VERSION ""

NS_ :

BS_:

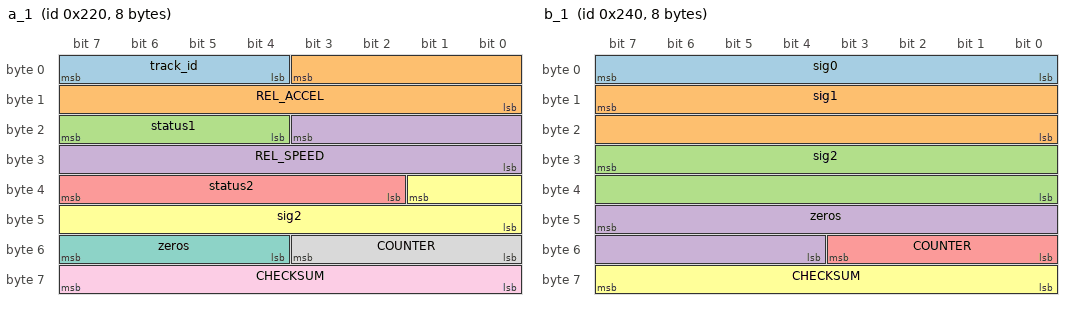
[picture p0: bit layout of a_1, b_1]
BO_ 544 a_1: 8 XXX
 SG_ track_id : 7|4@0+ (1,0) [0|15] "" XXX
 SG_ REL_ACCEL : 3|12@0+ (1,0) [0|31] "" XXX
 SG_ status1 : 23|4@0+ (1,0) [0|15] "" XXX
 SG_ REL_SPEED : 19|12@0+ (1,0) [0|65535] "" XXX
 SG_ status2 : 39|6@0+ (1,0) [0|15] "" XXX
 SG_ sig2 : 33|10@0+ (1,0) [0|255] "" XXX
 SG_ zeros : 55|4@0+ (1,0) [0|15] "" XXX
 SG_ COUNTER : 51|4@0+ (1,0) [0|15] "" XXX
 SG_ CHECKSUM : 63|8@0+ (1,0) [0|255] "" XXX

BO_ 576 b_1: 8 XXX
 SG_ sig0 : 7|8@0+ (1,0) [0|255] "" XXX
 SG_ sig1 : 15|16@0+ (1,0) [0|65535] "" XXX
 SG_ sig2 : 31|16@0+ (1,0) [0|255] "" XXX
 SG_ zeros : 47|12@0+ (1,0) [0|255] "" XXX
 SG_ COUNTER : 51|4@0+ (1,0) [0|15] "" XXX
 SG_ CHECKSUM : 63|8@0+ (1,0) [0|255] "" XXX

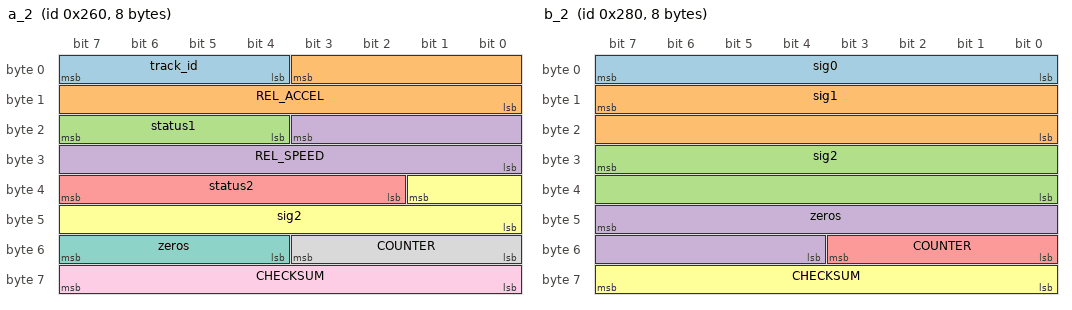
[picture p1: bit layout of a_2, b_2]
BO_ 608 a_2: 8 XXX
 SG_ track_id : 7|4@0+ (1,0) [0|15] "" XXX
 SG_ REL_ACCEL : 3|12@0+ (1,0) [0|31] "" XXX
 SG_ status1 : 23|4@0+ (1,0) [0|15] "" XXX
 SG_ REL_SPEED : 19|12@0+ (1,0) [0|65535] "" XXX
 SG_ status2 : 39|6@0+ (1,0) [0|15] "" XXX
 SG_ sig2 : 33|10@0+ (1,0) [0|255] "" XXX
 SG_ zeros : 55|4@0+ (1,0) [0|15] "" XXX
 SG_ COUNTER : 51|4@0+ (1,0) [0|15] "" XXX
 SG_ CHECKSUM : 63|8@0+ (1,0) [0|255] "" XXX

BO_ 640 b_2: 8 XXX
 SG_ sig0 : 7|8@0+ (1,0) [0|255] "" XXX
 SG_ sig1 : 15|16@0+ (1,0) [0|65535] "" XXX
 SG_ sig2 : 31|16@0+ (1,0) [0|255] "" XXX
 SG_ zeros : 47|12@0+ (1,0) [0|255] "" XXX
 SG_ COUNTER : 51|4@0+ (1,0) [0|15] "" XXX
 SG_ CHECKSUM : 63|8@0+ (1,0) [0|255] "" XXX

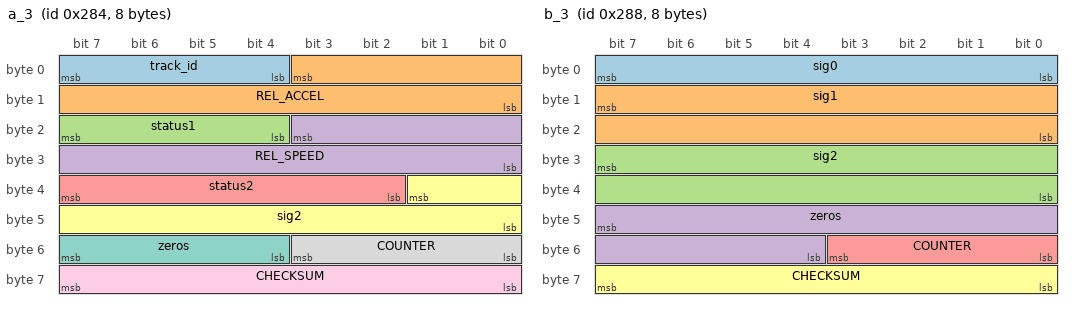
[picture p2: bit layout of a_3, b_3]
BO_ 644 a_3: 8 XXX
 SG_ track_id : 7|4@0+ (1,0) [0|15] "" XXX
 SG_ REL_ACCEL : 3|12@0+ (1,0) [0|31] "" XXX
 SG_ status1 : 23|4@0+ (1,0) [0|15] "" XXX
 SG_ REL_SPEED : 19|12@0+ (1,0) [0|65535] "" XXX
 SG_ status2 : 39|6@0+ (1,0) [0|15] "" XXX
 SG_ sig2 : 33|10@0+ (1,0) [0|255] "" XXX
 SG_ zeros : 55|4@0+ (1,0) [0|15] "" XXX
 SG_ COUNTER : 51|4@0+ (1,0) [0|15] "" XXX
 SG_ CHECKSUM : 63|8@0+ (1,0) [0|255] "" XXX

BO_ 648 b_3: 8 XXX
 SG_ sig0 : 7|8@0+ (1,0) [0|255] "" XXX
 SG_ sig1 : 15|16@0+ (1,0) [0|65535] "" XXX
 SG_ sig2 : 31|16@0+ (1,0) [0|255] "" XXX
 SG_ zeros : 47|12@0+ (1,0) [0|255] "" XXX
 SG_ COUNTER : 51|4@0+ (1,0) [0|15] "" XXX
 SG_ CHECKSUM : 63|8@0+ (1,0) [0|255] "" XXX

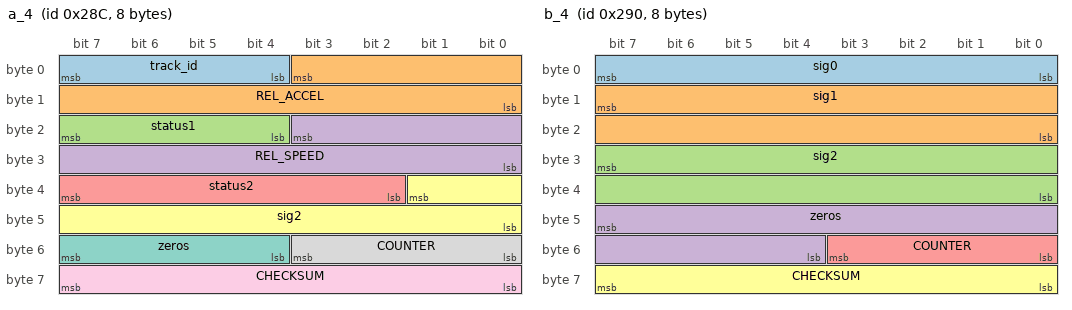
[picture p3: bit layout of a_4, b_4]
BO_ 652 a_4: 8 XXX
 SG_ track_id : 7|4@0+ (1,0) [0|15] "" XXX
 SG_ REL_ACCEL : 3|12@0+ (1,0) [0|31] "" XXX
 SG_ status1 : 23|4@0+ (1,0) [0|15] "" XXX
 SG_ REL_SPEED : 19|12@0+ (1,0) [0|65535] "" XXX
 SG_ status2 : 39|6@0+ (1,0) [0|15] "" XXX
 SG_ sig2 : 33|10@0+ (1,0) [0|255] "" XXX
 SG_ zeros : 55|4@0+ (1,0) [0|15] "" XXX
 SG_ COUNTER : 51|4@0+ (1,0) [0|15] "" XXX
 SG_ CHECKSUM : 63|8@0+ (1,0) [0|255] "" XXX

BO_ 656 b_4: 8 XXX
 SG_ sig0 : 7|8@0+ (1,0) [0|255] "" XXX
 SG_ sig1 : 15|16@0+ (1,0) [0|65535] "" XXX
 SG_ sig2 : 31|16@0+ (1,0) [0|255] "" XXX
 SG_ zeros : 47|12@0+ (1,0) [0|255] "" XXX
 SG_ COUNTER : 51|4@0+ (1,0) [0|15] "" XXX
 SG_ CHECKSUM : 63|8@0+ (1,0) [0|255] "" XXX

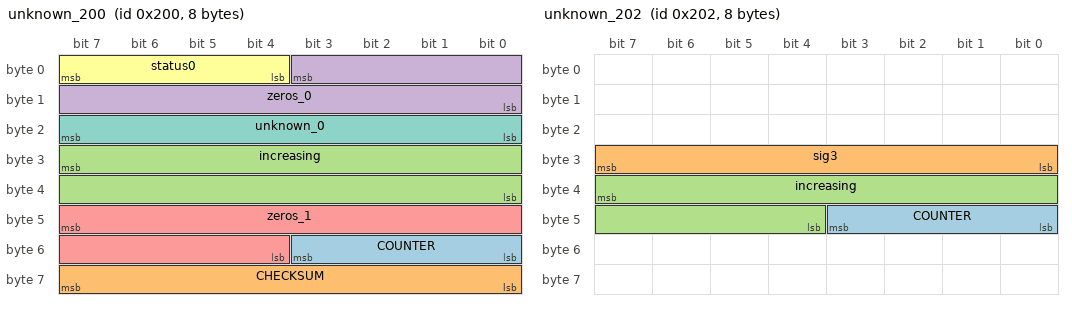
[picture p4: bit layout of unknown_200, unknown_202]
BO_ 512 unknown_200: 8 XXX
 SG_ COUNTER : 51|4@0+ (1,0) [0|15] "" XXX
 SG_ CHECKSUM : 63|8@0+ (1,0) [0|255] "" XXX
 SG_ increasing : 31|16@0+ (1,0) [0|255] "" XXX
 SG_ zeros_0 : 3|12@0+ (1,0) [0|63] "" XXX
 SG_ zeros_1 : 47|12@0+ (1,0) [0|63] "" XXX
 SG_ status0 : 7|4@0+ (1,0) [0|15] "" XXX
 SG_ unknown_0 : 23|8@0+ (1,0) [0|255] "" XXX

BO_ 514 unknown_202: 8 XXX
 SG_ COUNTER : 43|4@0+ (1,0) [0|15] "" XXX
 SG_ sig3 : 31|8@0+ (1,0) [0|65535] "" XXX
 SG_ increasing : 39|12@0+ (1,0) [0|15] "" XXX

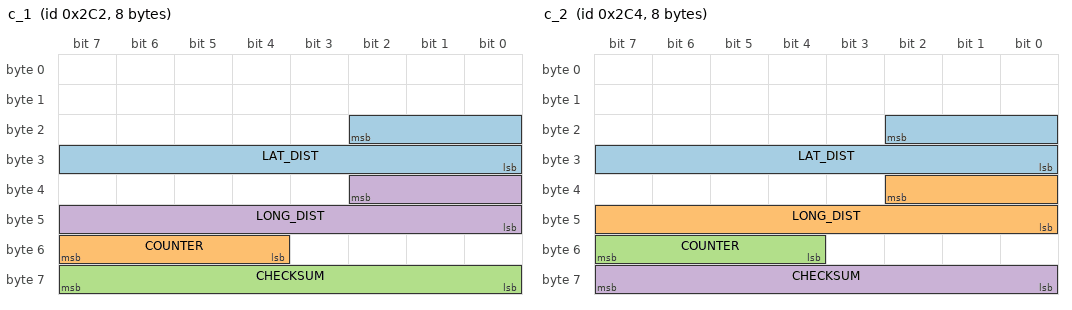
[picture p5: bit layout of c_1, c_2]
BO_ 706 c_1: 8 XXX
 SG_ LAT_DIST : 18|11@0+ (0.005,-1000) [0|2047] "m" XXX
 SG_ COUNTER : 55|4@0+ (1,0) [0|15] "" XXX
 SG_ CHECKSUM : 63|8@0+ (1,0) [0|255] "" XXX
 SG_ LONG_DIST : 34|11@0+ (0.073,0) [0|255] "m" XXX

BO_ 708 c_2: 8 XXX
 SG_ LAT_DIST : 18|11@0+ (0.005,-1000) [0|2047] "m" XXX
 SG_ LONG_DIST : 34|11@0+ (0.073,0) [0|255] "m" XXX
 SG_ COUNTER : 55|4@0+ (1,0) [0|15] "" XXX
 SG_ CHECKSUM : 63|8@0+ (1,0) [0|255] "" XXX

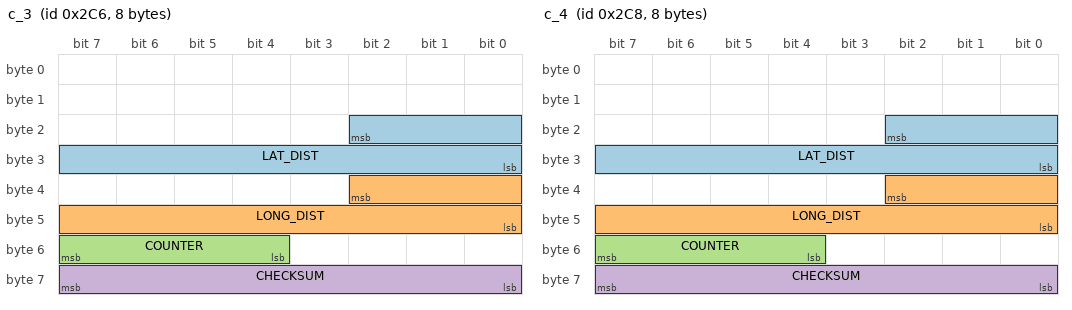
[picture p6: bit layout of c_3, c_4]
BO_ 710 c_3: 8 XXX
 SG_ LAT_DIST : 18|11@0+ (0.005,-1000) [0|2047] "m" XXX
 SG_ LONG_DIST : 34|11@0+ (0.073,0) [0|255] "m" XXX
 SG_ COUNTER : 55|4@0+ (1,0) [0|15] "" XXX
 SG_ CHECKSUM : 63|8@0+ (1,0) [0|255] "" XXX

BO_ 712 c_4: 8 XXX
 SG_ LAT_DIST : 18|11@0+ (0.005,-1000) [0|2047] "m" XXX
 SG_ LONG_DIST : 34|11@0+ (0.073,0) [0|255] "m" XXX
 SG_ COUNTER : 55|4@0+ (1,0) [0|15] "" XXX
 SG_ CHECKSUM : 63|8@0+ (1,0) [0|255] "" XXX

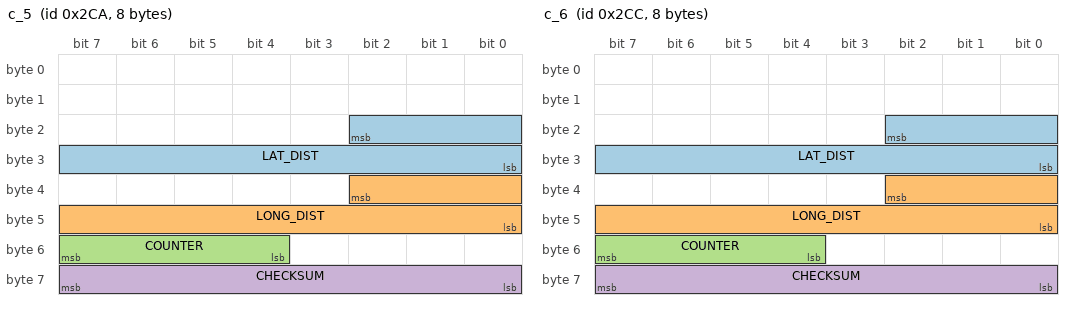
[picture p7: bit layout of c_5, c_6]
BO_ 714 c_5: 8 XXX
 SG_ LAT_DIST : 18|11@0+ (0.005,-1000) [0|2047] "m" XXX
 SG_ LONG_DIST : 34|11@0+ (0.073,0) [0|255] "m" XXX
 SG_ COUNTER : 55|4@0+ (1,0) [0|15] "" XXX
 SG_ CHECKSUM : 63|8@0+ (1,0) [0|255] "" XXX

BO_ 716 c_6: 8 XXX
 SG_ LAT_DIST : 18|11@0+ (0.005,-1000) [0|2047] "m" XXX
 SG_ LONG_DIST : 34|11@0+ (0.073,0) [0|255] "m" XXX
 SG_ COUNTER : 55|4@0+ (1,0) [0|15] "" XXX
 SG_ CHECKSUM : 63|8@0+ (1,0) [0|255] "" XXX

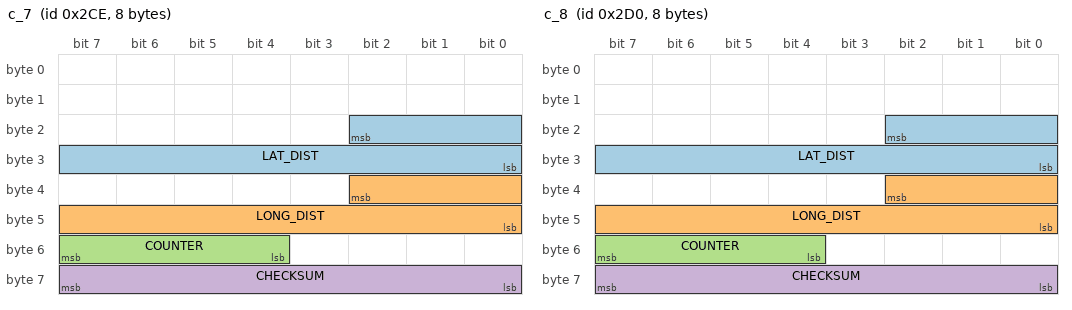
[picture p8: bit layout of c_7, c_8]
BO_ 718 c_7: 8 XXX
 SG_ LAT_DIST : 18|11@0+ (0.005,-1000) [0|2047] "m" XXX
 SG_ LONG_DIST : 34|11@0+ (0.073,0) [0|255] "m" XXX
 SG_ COUNTER : 55|4@0+ (1,0) [0|15] "" XXX
 SG_ CHECKSUM : 63|8@0+ (1,0) [0|255] "" XXX

BO_ 720 c_8: 8 XXX
 SG_ LAT_DIST : 18|11@0+ (0.005,-1000) [0|2047] "m" XXX
 SG_ LONG_DIST : 34|11@0+ (0.073,0) [0|255] "m" XXX
 SG_ COUNTER : 55|4@0+ (1,0) [0|15] "" XXX
 SG_ CHECKSUM : 63|8@0+ (1,0) [0|255] "" XXX

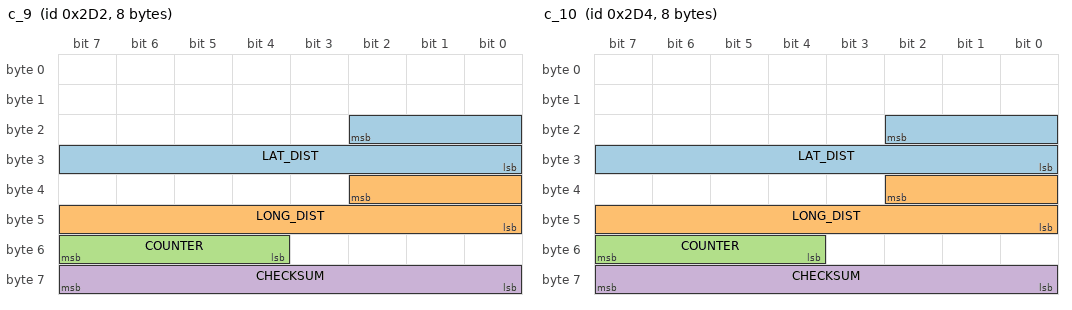
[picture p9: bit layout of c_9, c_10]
BO_ 722 c_9: 8 XXX
 SG_ LAT_DIST : 18|11@0+ (0.005,-1000) [0|2047] "m" XXX
 SG_ LONG_DIST : 34|11@0+ (0.073,0) [0|255] "m" XXX
 SG_ COUNTER : 55|4@0+ (1,0) [0|15] "" XXX
 SG_ CHECKSUM : 63|8@0+ (1,0) [0|255] "" XXX

BO_ 724 c_10: 8 XXX
 SG_ LAT_DIST : 18|11@0+ (0.005,-1000) [0|2047] "m" XXX
 SG_ LONG_DIST : 34|11@0+ (0.073,0) [0|255] "m" XXX
 SG_ COUNTER : 55|4@0+ (1,0) [0|15] "" XXX
 SG_ CHECKSUM : 63|8@0+ (1,0) [0|255] "" XXX

BO_ 674 d_1: 8 XXX
 SG_ REL_SPEED : 17|10@0+ (0.2857,-146.278) [0|1023] "m/s" XXX

BO_ 676 d_2: 8 XXX
 SG_ REL_SPEED : 17|10@0+ (0.2857,-146.278) [0|1023] "m/s" XXX

BO_ 678 d_3: 8 XXX
 SG_ REL_SPEED : 17|10@0+ (0.2857,-146.278) [0|1023] "m/s" XXX

BO_ 680 d_4: 8 XXX
 SG_ REL_SPEED : 17|10@0+ (0.2857,-146.278) [0|1023] "m/s" XXX

BO_ 682 d_5: 8 XXX
 SG_ REL_SPEED : 17|10@0+ (0.2857,-146.278) [0|1023] "m/s" XXX

BO_ 684 d_6: 8 XXX
 SG_ REL_SPEED : 17|10@0+ (0.2857,-146.278) [0|1023] "m/s" XXX

BO_ 686 d_7: 8 XXX
 SG_ REL_SPEED : 17|10@0+ (0.2857,-146.278) [0|1023] "m/s" XXX

BO_ 688 d_8: 8 XXX
 SG_ REL_SPEED : 17|10@0+ (0.2857,-146.278) [0|1023] "m/s" XXX

BO_ 690 d_9: 8 XXX
 SG_ REL_SPEED : 17|10@0+ (0.2857,-146.278) [0|1023] "m/s" XXX

BO_ 692 d_10: 8 XXX
 SG_ REL_SPEED : 17|10@0+ (0.2857,-146.278) [0|1023] "m/s" XXX

BO_ 672 NEW_MSG_5: 8 XXX
 SG_ NEW_SIGNAL_1 : 9|10@0+ (1,0) [0|1023] "" XXX
 SG_ NEW_SIGNAL_2 : 45|10@0+ (1,0) [0|1023] "" XXX

CM_ SG_ 80 Checksumme_Airbag_1 "Checksum Airbag_1";
CM_ SG_ 80 Zaehler_Airbag_1 "Counter Airbag_1";

CM_ SG_ 210 LM_Offset "centiNewton-meters for ease of calculation without FP math in Panda";
CM_ SG_ 210 Vib_Amp "Steering wheel haptic, amplitude";
CM_ SG_ 210 Vib_Freq "Steering wheel haptic, frequency";

CM_ SG_ 416 Zaehler_Bremse_1 "Counter Bremse_1";

CM_ SG_ 640 inneres_Motor_Moment "Engine Indicated Torque";
CM_ SG_ 640 Fahrerwunschmoment "Driver Requested Torque";
CM_ SG_ 640 mechanisches_Motor_Verlustmomen "Mechanical Torque Loss";
CM_ SG_ 640 Fahrpedalwert_oder_Drosselklapp "Accelerator Pedal or Throttle Position";
CM_ SG_ 640 Motordrehzahl "Engine Speed";
CM_ SG_ 640 Momentenangaben_ungenau "Approximate Torque Values";
CM_ SG_ 640 inneres_Motor_Moment_ohne_exter "Inner torque without external";

CM_ SG_ 644 MOB_CHECKSUM "Checksum MOB";
CM_ SG_ 644 MOB_COUNTER "Counter MOB";

CM_ SG_ 648 Minimales_Motormoment_bei_Zuend "Minimum Torque Adjustment";
CM_ SG_ 648 Begrenzungsmoment "Maximum Inner Torque";
CM_ SG_ 648 Bremstestschalter "Brake Test Switch";
CM_ SG_ 648 Soll_Geschwindigkeit_bei_GRA_Be "Desired Vehicle Speed";
CM_ SG_ 648 Bremslichtschalter "Brake Light Switch";
CM_ SG_ 648 Leerlaufsolldrehzahl__Motor_2_ "Target Idle Speed";
CM_ SG_ 648 Fahrzeuggeschwindigkeit "Vehicle Speed";
CM_ SG_ 648 Kuehlmitteltemperatur__Motor_2_ "Coolant Temperature";

CM_ SG_ 896 Drosselklappenpoti "Throttle Position";
CM_ SG_ 896 Motor_Wunschdrehzahl "Desired engine speed";
CM_ SG_ 896 Motordrehzahlbeeinflussung "Shift Target Influence";
CM_ SG_ 896 Fahrpedal_Rohsignal "Accelerator Pedal Position";
CM_ SG_ 896 Ansauglufttemperatur "Intake Air Temperature";
CM_ SG_ 896 Kein_E_Gas "ETB flag";
CM_ SG_ 896 Kein_Start_Stop "Start/stop flag";
CM_ SG_ 896 Rad_Wunschmoment "Desired wheel torque";

CM_ SG_ 912 GK1_Fa_Tuerkont "Status of the driver's door rotary latch";
CM_ SG_ 912 BSK_HL_geoeffnet "Status of the rear left door rotary latch";
CM_ SG_ 912 BSK_HR_geoeffnet "Status of the rear right door rotary latch";
CM_ SG_ 912 BSK_BT_geoeffnet "Status of the passenger door rotary latch";
CM_ SG_ 912 BSK_HD_Hauptraste "Status of trunk lid main detent";

CM_ SG_ 1088 Zaehler_Getriebe_1 "Counter Getriebe_1";
CM_ SG_ 1088 Waehlhebelposition__Getriebe_1_ "Gear Selector Position";
CM_ SG_ 1088 inneres_Soll_Motormoment "Desired Inner Torque";
CM_ SG_ 1088 Schaltabsicht "Shift Intent";
CM_ SG_ 1088 Wandlerverlustmoment "Converter Torque Loss";

CM_ SG_ 1056 Fehlerstatus_Aussentemp__4_1 "ambient temp error";
CM_ SG_ 1056 Fehlerstatus_Oeltemperatur_4_1 "oil temp error";
CM_ SG_ 1056 Fehlerst__Kuehlmitteltemp__4_1 "water temp error";
CM_ SG_ 1056 Aussentemperatur_gefiltert "outside temp, filtered";
CM_ SG_ 1056 Oeltemperatur_4_1 "kombi oil temperature";
CM_ SG_ 1056 Kuehlmitteltemp__4_1__Kombi_2_ "kombi coolant temperature";

CM_ SG_ 1096 Zaehler_Waehlhebel_1 "Counter Waehlhebel_1";

CM_ SG_ 1152 CHECKSUM "Checksum Motor_5";
CM_ SG_ 1152 Anlasser_Ausspuren "Starter Disable";
CM_ SG_ 1152 Anlasser_Freigabe "Starter Release";
CM_ SG_ 1152 Klimadrucksignal__Motor_5_ "Air conditioning pressure signal";
CM_ SG_ 1152 Kraftstoffverbrauchssignal "Fuel consumption signal";
CM_ SG_ 1152 K_hlerluefteransteuerung "Cooling fan control signal";
CM_ SG_ 1152 Klimakompressor_Leistungsreduzi "Air conditioning compressor power reduction flag";
CM_ SG_ 1152 Klimakompressor_aus__Motor_5_ "Air conditioning compressor";
CM_ SG_ 1152 Anlasser_Freigabe "Starter release";
CM_ SG_ 1152 OBD_2_Lampe "OBD light";
CM_ SG_ 1152 E_Gas_Lampe "ETB light";
CM_ SG_ 1152 Ladekontroll_Lampe "Charge light";
CM_ SG_ 1152 Vorgluehlampe__Motor_5_ "Glow light";

CM_ SG_ 1160 Zaehler_Motor_6 "Counter Motor_6";
CM_ SG_ 1160 Hoeheninfo__Motor_6_ "Altitude Correction";
CM_ SG_ 1160 Istmoment_f_r_Getriebe "Actual torque for gear";
CM_ SG_ 1160 Sollmoment_f_r_Getriebe "Target torque for gearbox";
CM_ SG_ 1160 Checksumme_Motor_6 "Checksum Motor_6";
CM_ SG_ 1160 GRA_Sollbeschleunigung "GRA target acceleration";
CM_ SG_ 1160 Ruckmeldung_Momenten "Feedback torque-integral gear intervention";

CM_ SG_ 1344 Zahler_Getriebe_2 "Counter Getriebe_2";
CM_ SG_ 1344 Hochschaltlampe "Upshift Flag";

CM_ SG_ 1386 ACA_V_Wunsch "255=unset";

CM_ SG_ 1408 Zaehler_Motor_Flexia "Counter Motor_Flexia";
CM_ SG_ 1408 Verbrennungsart "Type of combustion";
CM_ SG_ 1408 Max_Drehmoment "Maximum torque";
CM_ SG_ 1408 Drehzahl_MaxNorm "RPM of maximum torque";
CM_ SG_ 1408 Hubraum "Displacement";
CM_ SG_ 1408 Anzahl_Zylinder "Number of cylinders";
CM_ SG_ 1408 Anzahl_Ventile "Number of valves";
CM_ SG_ 1408 Ansaugsystem "Induction System";
CM_ SG_ 1408 Motorleistung "Maximum engine power";

CM_ SG_ 1416 Ladedruck "Boost Pressure";
CM_ SG_ 1416 Motordrehzahlgradient "Engine speed gradient";
CM_ SG_ 1416 Hoeheninfo__Motor_7_ "Altitude correction factor";
CM_ SG_ 1416 Oltemperatur "Oil temperature";

CM_ SG_ 1470 LDW_Direction "0=right,1=left";
CM_ SG_ 1470 XX_DLCORTLC1 "Might be DLC or TLC";
CM_ SG_ 1470 XX_DLCORTLC2 "Might be DLC or TLC, might have wrong size";

CM_ SG_ 1550 MFA_v_Signal_02 "0=km/h, 1=mph";

VAL_ 870 AWV_Text 0 "kein_Text" 1 "FrontAssist_aus" 2 "FrontAssist_startet" 3 "FrontAssist_Warnung" 4 "FrontAssist_Sens_reinig" 5 "FrontAssist_Failure" 6 "FrontAssist_Demo" 7 "Vorhalt" 8 "Bremsung_wird_gerade_durchgefuehrt" 9 "Sensor_not_verfuegbar" 10 "Sensor_reinigen" 11 "Service_notwendig_Failure" 12 "Funktion_vom_Fahrer_deactivated" 13 "Funktion_vom_Fahrer_activated" 14 "FrontAssist_zur_Zeit_not_verfuegbar__rev_Failure";
VAL_ 870 AWV_1_Freigabe 0 "nicht_freigegeben" 1 "freigegeben";
VAL_ 870 AWV_1_Prefill 0 "keine_Prefill_Anf" 1 "Prefill_Anf";
VAL_ 870 AWV_1_Parameter 0 "Defaultparametersatz" 1 "Par_leicht_erh_Empf" 2 "Par_erh_Empf" 3 "Par_hoechster_Empf";
VAL_ 870 AWV_only 0 "ACC_und_AWV_verbaut" 1 "AWV_ohne_ACC_verbaut";
VAL_ 870 AWV_CityANB_Auspraegung 0 "autom_Bremsung_im_ges_vBereich" 1 "autom_Bremsung_im_def_vBereich";
VAL_ 870 AWV_Halten 0 "keine_Anforderung" 1 "Anforderung_das_Fzg_im_Stillstand_zu_halten";
VAL_ 870 ANB_Teilbremsung_Freigabe 0 "Teilbremsung_nicht_freigegeben" 1 "Teilbremsung_freigegeben";
VAL_ 870 AWV_2_Status 0 "Lampe_aus" 1 "Lampe_ein";
VAL_ 870 AWV_2_Fehler 0 "Lampe_aus" 1 "Lampe_ein";
VAL_ 870 AWV_2_SU_Warnzeit 0 "frueh" 1 "normal" 2 "spaet" 3 "adaptiv";
VAL_ 870 AWV_2_SU_Bremsruck 0 "Bremsruck_deaktiviert" 1 "Bremsruck_aktiviert";
VAL_ 870 AWV_2_SU_Gong 0 "Gong_deaktiviert" 1 "Gong_aktiviert";
VAL_ 870 AWV_2_SU_Lampe 0 "Lampe_deaktiviert" 1 "Lampe_aktiviert";
VAL_ 870 AWV_2_Umfeldwarn 0 "keine_Warnung" 1 "Warnung";
VAL_ 870 AWV_2_Freigabe 0 "keine_Ruckfreigabe" 1 "Ruckfreigabe";
VAL_ 870 AWV_2_Ruckprofil 0 "kein_Ruck" 1 "Ruckprofil_1" 2 "Ruckprofil_2" 3 "Ruckprofil_3" 4 "Ruckprofil_4" 5 "Ruckprofil_5" 6 "not_erlaubt" 7 "not_erlaubt";
VAL_ 870 AWV_2_Warnton 0 "Aus" 1 "Ein";
VAL_ 870 AWV_2_Warnsymbol 0 "Aus" 1 "Ein";
VAL_ 870 AWV_Infoton 0 "Aus" 1 "Ein";
VAL_ 870 AWV_2_Gurtstraffer 0 "Gurt_not_straffen" 1 "Gurt_straffen";
VAL_ 870 AWV_Konfiguration_Menueanf 0 "Menue_deaktivieren" 1 "Menue_aktivieren";
VAL_ 870 AWV_Konfiguration_Vorw_Menueanf 0 "Menue_deaktivieren" 1 "Menue_aktivieren";
VAL_ 870 AWV_Konfiguration_Status 0 "AWV_inaktiv" 1 "AWV_aktiv";
VAL_ 870 AWV_Konfiguration_Vorw_Status 0 "AWV_Vorwarnung_inaktiv" 1 "AWV_Vorwarnung_aktiv";
VAL_ 870 AWV_2_Abstandswarnung 0 "kein_Warnhinweis" 1 "Warnhinweis";
VAL_ 870 ANB_Zielbremsung_Freigabe 0 "Zielbremsung_nicht_freigegeben" 1 "Zielbremsung_freigegeben";
VAL_ 870 ANB_CM_Anforderung 0 "keine_Anforderung" 1 "Anforderung_aktiv";

VAL_ 872 ACS_Sta_ADR 2 "ADR_passiv" 0 "ADR_nicht_aktiv" 1 "ADR_aktiv" 3 "irrev_Fehler" ;
VAL_ 872 ACS_ADR_Schub 1 "Verz_begr_auf_Schub" 0 "Verz_nicht_begr_auf_Schub" ;
VAL_ 872 ACS_Schubabsch 1 "SA_nicht_zulaessig" 0 "SA_zulaessig" ;
VAL_ 872 ACS_StSt_Info 3 "Systemfehler" 0 "Motorlauf_nn" 1 "Stoppverbot_Motoranlauf_nn" 2 "Motoranlauf_notwendig" ;
VAL_ 872 ACS_MomEingriff 1 "MomEingr_verhindern" 0 "keine_Beeinfl_MomEingr_Mot" ;
VAL_ 872 ACS_Typ_ACC 0 "Basis_ACC" 1 "ACC_mit_FollowToStop" 3 "frei" 2 "frei" ;
VAL_ 872 ACS_FreigSollB 0 "Sollbeschl_nicht_freigeg" 1 "Sollbeschl_freigeg" ;
VAL_ 872 ACS_Sollbeschl 2046 "ADR_nicht_aktiv" 2047 "Fehler" ;
VAL_ 872 ACS_Anhaltewunsch 0 "kein_Haltewunsch" 1 "Fzg_haelt_an" ;
VAL_ 872 ACS_Fehler 1 "Fehlerspeichereintrag" 0 "kein_Fehlerspeichereintrag" ;
VAL_ 872 ACS_zul_Regelabw 254 "ADR_nicht_aktiv" 255 "Fehler" ;
VAL_ 872 ACS_max_AendGrad 254 "Neutralwert" 0 "Neutralwert" 255 "Fehler" ;

VAL_ 978 LH2_Sta_HCA 0 "disabled" 1 "initializing" 2 "fault" 3 "ready" 4 "rejected" 5 "active";
VAL_ 1088 Waehlhebelposition__Getriebe_1_ 8 "P" 7 "R" 6 "N" 5 "D" 9 "U" 12 "S" 14 "T" 10 "T" 11 "T";

VAL_ 1386 ACA_StaACC 6 "ACC_rev_aus" 0 "Hauptschalter_aus" 4 "ACC_im_Hintergrund" 3 "ACC_aktiv" 1 "Reserve" 2 "ACC_passiv" 7 "ACC_irrev_aus" 5 "frei" ;
VAL_ 1386 ACA_ID_StaACC 0 "keine_Anzeige" ;
VAL_ 1386 ACA_Fahrerhinw 1 "Ein" 0 "Aus" ;
VAL_ 1386 ACA_AnzDisplay 1 "Anzeige_erw" 0 "Anzeige_nicht_erw" ;
VAL_ 1386 ACA_Zeitluecke 3 "Zeitluecke3" 10 "Zeitluecke10" 4 "Zeitluecke4" 14 "Zeitluecke14" 11 "Zeitluecke11" 2 "Zeitluecke2" 13 "Zeitluecke13" 9 "Zeitluecke9" 1 "Zeitluecke1" 8 "Zeitluecke8" 5 "Zeitluecke5" 15 "Zeitluecke15" 0 "nicht_definiert" 12 "Zeitluecke12" 6 "Zeitluecke6" 7 "Zeitluecke7" ;
VAL_ 1386 ACA_V_Wunsch 255 "kein_Wert_im_Speicher" ;
VAL_ 1386 ACA_kmh_mph 0 "km_h" 1 "mph" ;
VAL_ 1386 ACA_Akustik1 0 "kein_Gong" 1 "Gong" ;
VAL_ 1386 ACA_Akustik2 0 "kein_Summer" 1 "Summer" ;
VAL_ 1386 ACA_PrioDisp 1 "mittlere_Prio" 3 "keine_Anzeige_Anf" 0 "hohe_Prio" 2 "niedrige_Prio" ;
VAL_ 1386 ACA_gemZeitl 6 "Zeitluecke6" 2 "Zeitluecke2" 7 "Zeitluecke7" 13 "Zeitluecke13" 11 "Zeitluecke11" 4 "Zeitluecke4" 8 "Zeitluecke8" 12 "Zeitluecke12" 10 "Zeitluecke10" 0 "Kein_Objekt_erfasst" 1 "Zeitluecke1" 3 "Zeitluecke3" 9 "Zeitluecke9" 15 "Zeitluecke15" 14 "Zeitluecke14" 5 "Zeitluecke5" ;
VAL_ 1386 ACA_ACC_Verz 0 "ACC_verzoegert_nicht" 1 "ACC_verzoegert" ;
VAL_ 1386 ACA_StaGRA 3 "GRA_aktiv" 4 "GRA_uebertreten" 2 "GRA_passiv" 0 "Hauptschalter_aus" 6 "frei" 7 "GRA_Fehler" 1 "Reserve" 5 "frei" ;
VAL_ 1386 ACA_ID_StaGRA 0 "keine_Anzeige" ;
VAL_ 1386 ACA_Codierung 0 "ACC" 1 "GRA" ;
VAL_ 1386 ACA_Tachokranz 0 "nicht_beleuchtet" 1 "beleuchtet" ;
VAL_ 1386 ACA_Aend_Zeitluecke 1 "Anzeige_angef" 0 "keine_Anzeige" ;

VAL_ 1472 EP1_Fehler_Sta 0 "volle_Funktion" 1 "linke_Seite_fehlerhaft" 2 "rechte_Seite_fehlerhaft" 3 "beide_Seiten_fehlerhaft";
VAL_ 1472 EP1_Sta_EPB 0 "Bremse_geoeffnet" 1 "Bremse_geschlossen";
VAL_ 1472 EP1_Sta_Schalter 0 "volle_Funktion" 1 "Schalter_ausser_Funktion";
VAL_ 1472 EP1_Spannkraft 31 "Fehler";
VAL_ 1472 EP1_Schalterinfo 0 "keine_Fahreranforderung" 1 "Fahreranforderung_oeffnen" 2 "Fahreranforderung_schliessen" 3 "Schalterfehler";
VAL_ 1472 EP1_Sta_NWS 0 "volle_Funktion" 1 "keine_Funktion";
VAL_ 1472 EP1_Fehlereintr 0 "kein_Fehlerspeichereintrag" 1 "Fehlerspeichereintrag";
VAL_ 1472 EP1_Freigabe_Ver 0 "Verzoegerungsanf_nicht_freigegeb" 1 "Verzoegerungsanf_freigegeben";
VAL_ 1472 EP1_AutoHold_zul 0 "Pers_nicht_zulaessig" 1 "Pers_zulaessig";
VAL_ 1472 EP1_AutoHold_aktiv 0 "nein" 1 "ja";
VAL_ 1472 EP1_SleepInd 0 "CAN_wird_benoetigt" 1 "Sleep_bereit";
VAL_ 1472 EP1_Status_Kl_15 0 "Kl_15_aus" 1 "Kl_15_ein";
VAL_ 1472 EP1_Lampe_AutoP 0 "Lampe_aus" 1 "Lampe_ein";
VAL_ 1472 EP1_Bremslicht 0 "Aus" 1 "Ein";
VAL_ 1472 EP1_Warnton1 0 "Aus" 1 "Ein";
VAL_ 1472 EP1_Warnton2 0 "Aus" 1 "Ein";
VAL_ 1472 EP1_AnfShLock 0 "Aus" 1 "Ein";
VAL_ 1472 EPB_Autoholdlampe 0 "Lampe_aus" 1 "Lampe_ein";
VAL_ 1472 EP1_QualNeigWi 0 "gueltiger_Wert" 1 "Ersatz_Init_oder_Fehlerwert";
VAL_ 1472 EP1_KuppModBer 0 "Kuppsensor_aus_Modbereich" 1 "Kupplsensor_im_Modbereich" 2 "Sensorsignal_ungenau" 3 "Sensor_defekt";
VAL_ 1472 EP1_HydrHalten 0 "Fzg_nicht_hydr_geh" 1 "Fzg_hydr_geh";
VAL_ 1472 EP1_Fkt_Lampe 0 "Lampe_aus" 1 "Lampe_ein";
VAL_ 1472 EP1_Warnton 0 "Warnton_aus" 1 "Warnton_an";
VAL_ 1472 EP1_Fehler_BKL 0 "BKL_aus" 1 "BKL_an";
VAL_ 1472 EP1_Fehler_gelb 0 "Lampe_aus" 1 "Lampe_ein";
